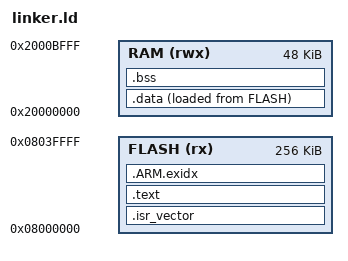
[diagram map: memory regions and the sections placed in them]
ENTRY(Reset_Handler)

MEMORY
{
    FLASH (rx)  : ORIGIN = 0x08000000, LENGTH = 256K
    RAM   (rwx) : ORIGIN = 0x20000000, LENGTH = 48K
}

SECTIONS
{
    .isr_vector ORIGIN(FLASH) :
    {
        KEEP(*(.isr_vector))
    } > FLASH

    .text :
    {
        *(.text*)
        *(.rodata*)
    } > FLASH

    .ARM.exidx :
    {
        *(.ARM.exidx*)
    } > FLASH

    .data :
    {
        *(.data*)
    } > RAM AT > FLASH

    .bss (NOLOAD) :
    {
        *(.bss*)
        *(COMMON)
    } > RAM

    /DISCARD/ :
    {
        *(.comment*)
        *(.note*)
    }
}
